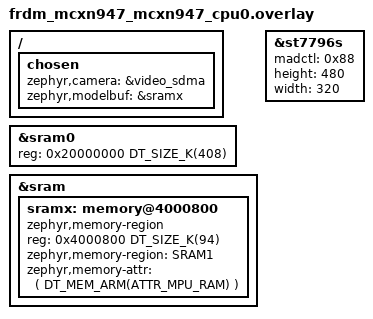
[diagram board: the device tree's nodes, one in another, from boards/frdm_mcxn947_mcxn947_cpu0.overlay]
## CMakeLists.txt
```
# Copyright 2024, NXP
#
# SPDX-License-Identifier: Apache-2.0

cmake_minimum_required(VERSION 3.20.0)

# Add shields for displays and cameras
if("${BOARD}" MATCHES "mimxrt1060_evk")
	set(SHIELD dvp_fpc24_mt9m114;rk043fn66hs_ctg)
elseif("${BOARD}" MATCHES "frdm_mcxn947")
	set(SHIELD lcd_par_s035_8080)
endif()

find_package(Zephyr REQUIRED HINTS $ENV{ZEPHYR_BASE})
project(facialdetect)

list(APPEND app_sources src/main.c)

list(APPEND app_sources src/face_det.cpp)
FILE(GLOB model_sources src/model/*.cpp)
list(APPEND app_sources ${model_sources})
list(APPEND app_sources img/image_draw.c)
list(APPEND app_sources img/image_conv.c)

zephyr_include_directories(${CMAKE_CURRENT_SOURCE_DIR}/src/model)
set(TFLITE_DIR "${CMAKE_CURRENT_SOURCE_DIR}/../../../modules/lib/tflite-micro")
zephyr_include_directories(${TFLITE_DIR})
zephyr_include_directories(${TFLITE_DIR}/third_party/flatbuffers/include)
zephyr_include_directories(${TFLITE_DIR}/third_party/gemmlowp)
zephyr_include_directories(${TFLITE_DIR}/third_party/ruy)

add_library(libtflm STATIC IMPORTED GLOBAL)
if (DEFINED CONFIG_CPU_CORTEX_M7)
	set_target_properties(libtflm PROPERTIES IMPORTED_LOCATION ${TFLITE_DIR}/lib/cm7/armgcc/libtflm.a)
elseif (DEFINED CONFIG_CPU_CORTEX_M33)
	set_target_properties(libtflm PROPERTIES IMPORTED_LOCATION ${TFLITE_DIR}/lib/cm33/armgcc/libtflm.a)
else()
	message(FATAL_ERROR "libtflm.a for this core not supported")
endif()

if (DEFINED CONFIG_MCUX_HAS_NPU)
	zephyr_include_directories(${CMAKE_CURRENT_SOURCE_DIR}/src/model/model_npu)
	zephyr_include_directories(${TFLITE_DIR}/tensorflow/lite/micro/kernels/neutron)
	zephyr_include_directories(${TFLITE_DIR}/third_party/neutron/common/include)
	zephyr_include_directories(${TFLITE_DIR}/third_party/neutron/driver/include)

	FILE(GLOB modelnpu_sources src/model/model_npu/*.cpp)
	list(APPEND app_sources ${modelnpu_sources})
	list(APPEND app_sources src/model/model_npu/model_data.s)
	list(APPEND app_sources ${TFLITE_DIR}/tensorflow/lite/micro/kernels/neutron/neutron.cpp)

	add_library(libNeutronDriver STATIC IMPORTED GLOBAL)
	set_target_properties(libNeutronDriver PROPERTIES IMPORTED_LOCATION ${TFLITE_DIR}/third_party/neutron/mcxn/libNeutronDriver.a)
	add_library(libNeutronFirmware STATIC IMPORTED GLOBAL)
	set_target_properties(libNeutronFirmware PROPERTIES IMPORTED_LOCATION ${TFLITE_DIR}/third_party/neutron/mcxn/libNeutronFirmware.a)
	target_link_libraries(app PUBLIC libNeutronDriver libNeutronFirmware)
else() # CONFIG_MCUX_HAS_NPU not defined
	zephyr_include_directories(${CMAKE_CURRENT_SOURCE_DIR}/src/model/model_sw)

	FILE(GLOB modelsw_sources src/model/model_sw/*.cpp)
	list(APPEND app_sources ${modelsw_sources})
	list(APPEND app_sources img/image_resize_nearest.c)
endif() # CONFIG_MCUX_HAS_NPU
target_link_libraries(app PUBLIC libtflm)

zephyr_include_directories(${CMAKE_CURRENT_SOURCE_DIR}/img)
zephyr_include_directories(${CMAKE_CURRENT_SOURCE_DIR}/src/font)
list(APPEND app_sources src/display.c)
list(APPEND app_sources src/convert.c)

target_compile_definitions(app PRIVATE TF_LITE_STATIC_MEMORY)
target_compile_options(app PRIVATE -Wno-psabi)
target_sources(app PRIVATE ${app_sources})
```

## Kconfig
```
# Copyright 2024 NXP
# SPDX-License-Identifier: Apache-2.0

# Config options for app

config APP_LOG_LEVEL
	int "Log Level for application"

config APP_TENSOR_ARENA_SIZE_KB
	int "size of arena in KB"
	default 200

config APP_CONVERT_DISPLAY
	bool "converts video buffer before writing to display"
	depends on DISPLAY

config APP_RESIZE_FOR_MODEL
	bool "Resizes frame before model processes"

config APP_DISPLAY_BANNER
	bool "Displays text banner on bottom of display, with inference results"
	depends on DISPLAY

config MCUX_HAS_NPU
	bool "SOC has NPU"

if APP_CONVERT_DISPLAY
	config CONVDISP_BUF_POOL_SZ_MAX
		int "Maximum size in bytes of each buffer in the CONVDISP pool"

	config CONVDISP_BUF_POOL_NUM_MAX
		int "Maximum number of buffers in the CONVDISP pool"

	config APP_USE_PXP
		bool "use PXP for conversion"

	if APP_USE_PXP
		config APP_PXP_FLIP_HORIZONTAL
			bool "uses PXP to flip frame horizontally"
	endif # APP_USE_PXP
endif # APP_CONVERT_DISPLAY

if APP_RESIZE_FOR_MODEL
	config APP_EXTRACT_WIDTH
		int "width of image extracted from camera frame in pixels"

	config APP_EXTRACT_HEIGHT
		int "height of image extracted from camera frame in pixels"
endif # APP_RESIZE_FOR_MODEL

source "Kconfig.zephyr"
```

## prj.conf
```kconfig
#
# Copyright 2024, NXP
#
# SPDX-License-Identifier: Apache-2.0
#

CONFIG_APP_LOG_LEVEL=3

CONFIG_DISPLAY=y
CONFIG_DISPLAY_LOG_LEVEL_ERR=y
CONFIG_VIDEO=y

CONFIG_LOG=y
CONFIG_SHELL=y
CONFIG_DEVICE_SHELL=y
CONFIG_PRINTK=y
CONFIG_THREAD_RUNTIME_STATS=y
CONFIG_SCHED_THREAD_USAGE=y
CONFIG_STD_CPP11=y

CONFIG_BUILD_OUTPUT_HEX=y

CONFIG_HEAP_MEM_POOL_SIZE=16384
CONFIG_NO_OPTIMIZATIONS=y
CONFIG_MAIN_STACK_SIZE=16000
CONFIG_IDLE_STACK_SIZE=1024
CONFIG_ISR_STACK_SIZE=8096

CONFIG_CPP=y
CONFIG_REQUIRES_FULL_LIBCPP=y
CONFIG_FPU=y
CONFIG_FP_HARDABI=y

# using Picolib has errors compiling C++ math
CONFIG_NEWLIB_LIBC=y
```

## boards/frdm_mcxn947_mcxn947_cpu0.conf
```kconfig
#
# Copyright 2024, NXP
#
# SPDX-License-Identifier: Apache-2.0
#

CONFIG_MCUX_HAS_NPU=y

# Workaround for issue where SDMA driver needs to start before camera, so that
# clock output will be generated for camera device
CONFIG_CHECK_INIT_PRIORITIES=n

CONFIG_HEAP_MEM_POOL_SIZE=41000

# Buffer size 320W x 15H x 2BPP x 2(SmartDMA) + 36
CONFIG_VIDEO_BUFFER_POOL_SZ_MAX=19236
CONFIG_VIDEO_BUFFER_POOL_NUM_MAX=3
```

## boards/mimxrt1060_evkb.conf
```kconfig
#
# Copyright 2024, NXP
#
# SPDX-License-Identifier: Apache-2.0
#

CONFIG_VIDEO_MCUX_CSI_INIT_PRIORITY=60
CONFIG_VIDEO_INIT_PRIORITY=61
CONFIG_CHECK_INIT_PRIORITIES=n

CONFIG_APP_CONVERT_DISPLAY=y
CONFIG_DMA=y
CONFIG_APP_USE_PXP=y
CONFIG_APP_PXP_FLIP_HORIZONTAL=y
CONFIG_APP_RESIZE_FOR_MODEL=y
CONFIG_APP_DISPLAY_BANNER=y

# Extraction is twice the model input size of 160 x 128
CONFIG_APP_EXTRACT_WIDTH=320
CONFIG_APP_EXTRACT_HEIGHT=256

# buffer size 261,120 = 480 * 272 * 2
CONFIG_CONVDISP_BUF_POOL_SZ_MAX=261120
CONFIG_CONVDISP_BUF_POOL_NUM_MAX=2
```

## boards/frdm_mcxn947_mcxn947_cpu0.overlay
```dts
/*
 * Copyright 2024, NXP
 *
 * SPDX-License-Identifier: Apache-2.0
 */

/* Resize SRAMX to avoid memory used by SmartDMA firmware */
/delete-node/ &sramx;

/ {
	chosen {
		zephyr,camera = &video_sdma;

		/* Use buffer for model to stitch camera slices together.
		 * Place model buffer in SRAMX */
		zephyr,modelbuf = &sramx;
	};
};

&sram0 {
	/* Increase size of SRAM region */
	reg = < 0x20000000 DT_SIZE_K(408) >;
};

&sram {
	sramx: memory@4000800 {
		compatible = "zephyr,memory-region", "mmio-sram";
		/* Avoid SRAMX memory used by SmartDMA firmware */
		reg = < 0x4000800  DT_SIZE_K(94) >;
		zephyr,memory-region = "SRAM1";
		zephyr,memory-attr = <( DT_MEM_ARM(ATTR_MPU_RAM) )>;
	};
};

/* Rotate the display to portrait mode */
&st7796s {
	madctl = <0x88>;
	height = <480>;
	width = <320>;
};
```

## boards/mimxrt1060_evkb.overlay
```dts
/*
 * Copyright 2024, NXP
 *
 * SPDX-License-Identifier: Apache-2.0
 */

 / {
	chosen {
		zephyr,arena = &ocram2; /* Place tensorArena in OCRAM2 */
	};
};

/* Increase DTCM for model. */
&itcm {
	reg = < 0x0 DT_SIZE_K(64) >;
};
&dtcm {
	reg = < 0x20000000 DT_SIZE_K(384) >;
};
&ocram {
	reg = < 0x20280000 DT_SIZE_K(64) >;
};
&flexram {
	flexram,bank-spec = <FLEXRAM_OCRAM>,
			    <FLEXRAM_OCRAM>,
			    <FLEXRAM_DTCM>,
			    <FLEXRAM_DTCM>,
			    <FLEXRAM_DTCM>,
			    <FLEXRAM_DTCM>,
			    <FLEXRAM_DTCM>,
			    <FLEXRAM_DTCM>,
			    <FLEXRAM_ITCM>,
			    <FLEXRAM_ITCM>,
			    <FLEXRAM_DTCM>,
			    <FLEXRAM_DTCM>,
			    <FLEXRAM_DTCM>,
			    <FLEXRAM_DTCM>,
			    <FLEXRAM_DTCM>,
			    <FLEXRAM_DTCM>;
};
```

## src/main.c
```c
/*
 * Copyright 2024, NXP
 * Copyright (c) 2019 Linaro Limited, for sample:
 *    https://github.com/zephyrproject-rtos/zephyr/blob/main/samples/subsys/video/capture/src/main.c
 *
 * Copyright (c) 2019 Jan Van Winkel <jan.van_winkel@dxplore.eu>, for sample:
 *    https://github.com/zephyrproject-rtos/zephyr/blob/main/samples/drivers/display/src/main.c
 *
 * Based on ST7789V sample:
 *    Copyright (c) 2019 Marc Reilly
 *
 * SPDX-License-Identifier: Apache-2.0
 *
 * Application Overview:
 * The main thread runs in a loop, dequeuing buffers from the video driver,
 * formatting and writing to the display, then resizing and sending to the
 * inference model for object detection.  If detected, the model returns
 * coordinates of the object, and rectangles are drawn for the display.
 * Inferencing is done in a separate thread, giving priority to updating the
 * display.
 * 
 * on MCX N947:
 * This SOC provides some challenge due to the limited RAM available.  The
 * LCD-PAR-S035 display is oriented in portrait mode to align with the camera.
 * To conserve RAM, the camera frame is shown on the upper half of the display,
 * at 320 x 240.  The lower half displays text, and is only updated with new
 * inference results.
 * 
 * To conserve RAM, the video driver buffers are partial slices of the full frame.
 * This reduces the buffer size required.  The video driver reports the number
 * of slices in a frame in caps.vbuf_per_frame.  And each buffer dequeued
 * provides frame_idx for that slice.  The LCD-PAR-S035 module is a smart
 * display, and partial frames can be written directly to the display.  Then
 * the slice buffer is copied to the input buffer for the model and converted to
 * RGB888.  That input is also resized for the model.  The rectangles are also
 * drawn on the slices, using the same video slice buffers before they are
 * written to the display.  To provide a cleaner look, the rectangle locations
 * are only changed at the start of a new frame.  And the previous rectangles
 * are "erased" completely before drawing new rectangles.
 * 
 * on RT1060:
 * This platform is easier with a large SDRAM, and plenty of room for buffers.
 * The video driver provides full frame buffers.  These are converted using the
 * PXP to flip the image horizontally, like looking in a mirror.  On this display,
 * the text is displayed in a banner at the bottom of the display, and the results
 * are updated from the inference.  The bottom of the full video buffer is
 * excluded when writing to the display, since the banner is drawn there.  After
 * writing to the display, the same buffer is passed to the inference thread. A
 * queue is used when passing this buffer.  The inference thread will get the
 * most recent buffer in that queue, and return any other buffers in that queue
 * to the video driver.  Rectangles are easier on this platform since the video
 * and display driver use a full frame.  If detected, the full rectangles are
 * drawn on each frame, and location updated after a new inference result.
 */

#include <zephyr/device.h>
#include <zephyr/devicetree.h>
#include <stdio.h>
#include <zephyr/kernel.h>
#include "FacialDetect.h"

#ifdef CONFIG_LOG
#define LOG_LEVEL CONFIG_LOG_DEFAULT_LEVEL
#include <zephyr/logging/log.h>
LOG_MODULE_REGISTER(app, CONFIG_APP_LOG_LEVEL);
#endif /* CONFIG_LOG */

struct display_buffer_descriptor strbuf_desc;

#include <zephyr/drivers/display.h>
#include <zephyr/drivers/video.h>
#include "display_app.h"
#include "convert.h"

const struct device *display_dev;

volatile static uint32_t __attribute((aligned(4))) vbuf_idx = 0;

#include "model.h"

K_THREAD_STACK_DEFINE(inf_thread_stack_area, THREAD_INF_STACKSIZE);
static struct k_thread inf_thread_data;

struct k_fifo inf_fifo;  /* FIFO for buffers to inference */

int main(void)
{
	printk("Zephyr Facial Detection Demo\r\n");
	printk("Model: %s\r\n", MODEL_GetModelName());

	struct video_buffer *buffers[CONFIG_VIDEO_BUFFER_POOL_NUM_MAX], *vbuf;
	struct display_buffer_descriptor buf_desc;
	void *convdisp_buf = NULL;
	rect_buf_params_t rect_params;

	display_dev = DEVICE_DT_GET(DT_CHOSEN(zephyr_display));
	if (!device_is_ready(display_dev)) {
		LOG_ERR("Device not ready, aborting test");
		return -1;
	}

	if (convdisp_init(DT_PROP(DT_CHOSEN(zephyr_display), width),
		DT_PROP(DT_CHOSEN(zephyr_display), height))) {
		LOG_ERR("convdisp_init() failed\n");
		return -1;
	}

	const struct device *const video = DEVICE_DT_GET(DT_CHOSEN(zephyr_camera));

	if (!device_is_ready(video)) {
		LOG_ERR("%s: device not ready.\n", video->name);
		return -1;
	}

	int i = 0;
	unsigned int frame = 0;

	LOG_DBG("- Device name: %s\n", video->name);

	/* Get capabilities */
	struct video_caps caps;
	if (video_get_caps(video, VIDEO_EP_OUT, &caps)) {
		LOG_ERR("Unable to retrieve video capabilities");
		return -1;
	}

	LOG_DBG("- Capabilities:\n");
	while (caps.format_caps[i].pixelformat) {
		const struct video_format_cap *fcap = &caps.format_caps[i];
		/* fourcc to string */
		LOG_DBG("  %c%c%c%c width [%u; %u; %u] height [%u; %u; %u]\n",
		       (char)fcap->pixelformat,
		       (char)(fcap->pixelformat >> 8),
		       (char)(fcap->pixelformat >> 16),
		       (char)(fcap->pixelformat >> 24),
		       fcap->width_min, fcap->width_max, fcap->width_step,
		       fcap->height_min, fcap->height_max, fcap->height_step);
		i++;
	}

	/* Get default/native format */
	struct video_format fmt;
	if (video_get_format(video, VIDEO_EP_OUT, &fmt)) {
		LOG_ERR("Unable to retrieve video format");
		return -1;
	}

	LOG_DBG("- Default format: %c%c%c%c %ux%u\n", (char)fmt.pixelformat,
	       (char)(fmt.pixelformat >> 8),
	       (char)(fmt.pixelformat >> 16),
	       (char)(fmt.pixelformat >> 24),
	       fmt.width, fmt.height);

	/* Size to allocate for each buffer */
	size_t bsize;
	bsize = fmt.pitch * fmt.height / caps.vbuf_per_frame;

	/* Alloc video buffers and enqueue for capture */
	for (i = 0; i < ARRAY_SIZE(buffers); i++) {
		buffers[i] = video_buffer_alloc(bsize);
		if (buffers[i] == NULL) {
			LOG_ERR("Unable to alloc video buffer");
			return -1;
		}

		video_enqueue(video, VIDEO_EP_OUT, buffers[i]);
	}

	/* configure display buffer */
	uint16_t y_step;

	y_step = fmt.height / caps.vbuf_per_frame;
	buf_desc.buf_size = bsize;
	buf_desc.width = fmt.width;
	buf_desc.pitch = fmt.width;
	buf_desc.height = y_step;
	#ifdef CONFIG_APP_DISPLAY_BANNER
		buf_desc.height -= BANNER_HEIGHT;
	#endif

	/* use a video buffer to initially draw the display brackground */
	display_background(buffers[0]->buffer);

	/* Start video capture */
	if (video_stream_start(video)) {
		LOG_ERR("Unable to start capture (interface)");
		return -1;
	}

	LOG_DBG("Capture started\n");

	/* Create inference thread */
	inf_thread_config_t inf_config;

	inf_config.frameWidth = fmt.width;
	inf_config.fullFrameHeight = fmt.height;
	inf_config.singleFrameHeight = buf_desc.height;

	k_fifo_init(&inf_fifo);

	k_thread_create(&inf_thread_data, inf_thread_stack_area,
		K_THREAD_STACK_SIZEOF(inf_thread_stack_area),
		inference_thread, &inf_config, &inf_fifo, NULL,
		THREAD_PRIORITY_INF, 0, K_FOREVER);
	k_thread_name_set(&inf_thread_data, "inference_thread");

	uint8_t inf_frame_count = 0;
	bool inference_enabled = false;

	inf_results_t infResults;
	inf_results_t *frame_infResults;
	if (caps.vbuf_per_frame > 1U) {
		/* Inference results are synced at the start of each full video
		 * frame, to keep rectangles consistent in that frame.  Display
		 * will use the local copy of the results. */
		frame_infResults = &infResults;
	} else {
		/* When video provides full frame, display can use the global
		 * inference results, and avoid copying the results every frame */
		frame_infResults = &g_InfResults;
	}

	rect_params.width = buf_desc.width;
	rect_params.height = buf_desc.height;
	rect_params.slices_per_frame = caps.vbuf_per_frame;

	while (1) {
		int err;

		/* Grab video frames */
		err = video_dequeue(video, VIDEO_EP_OUT, &vbuf, K_FOREVER);
		if (err) {
			LOG_ERR("Unable to dequeue video buf");
			return -1;
		}

		LOG_DBG("\rGot frame %u! size: %u; timestamp %u ms",
		       frame++, vbuf->bytesused, vbuf->timestamp);

		convdisp(vbuf->buffer, (uint8_t **) &convdisp_buf,
			vbuf->bytesused, K_FOREVER);

		if(caps.vbuf_per_frame > 1) {
			if(vbuf->frame_idx == 0) {
				sync_slice_rectangles(frame_infResults);
			}
		#if DT_HAS_CHOSEN(zephyr_modelbuf)
			copy_slice_to_model_input(vbuf->frame_idx,
				(uint32_t) convdisp_buf, fmt.width, y_step,
				caps.vbuf_per_frame);
		#endif /* #if DT_HAS_CHOSEN(zephyr_modelbuf) */
		}

		rect_params.buf = (uint16_t *) convdisp_buf;
		rect_params.frame_idx = vbuf->frame_idx;
		display_rectangles(&rect_params, frame_infResults);

		/* Write the video buffer out to the display */
		display_write(display_dev, 0, y_step * vbuf->frame_idx, &buf_desc, convdisp_buf);

		if(inference_enabled) {
			/* wake inf_thread if it is waiting for buffer */
			k_fifo_alloc_put(&inf_fifo, convdisp_buf);
		} else {
			if(inf_frame_count >= caps.vbuf_per_frame) {
				/* wait for first full frame before starting
				 * inference thread */
				k_fifo_alloc_put(&inf_fifo, convdisp_buf);
				k_thread_start(&inf_thread_data);
				inference_enabled = true;
			} else {
				inf_frame_count++;
				/* free buffer for next conversion */
				convdisp_enqueue(convdisp_buf);
			}
		}

		/* vbuf already used, re-use this buffer to write results to
		 * display, before giving back to video driver. */
		display_results((uint16_t *)vbuf->buffer);

		err = video_enqueue(video, VIDEO_EP_OUT, vbuf);
		if (err) {
			LOG_ERR("Unable to requeue video buf");
			return -1;
		}
	}
}
```

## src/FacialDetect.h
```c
/*
 * Copyright 2024, NXP
 *
 * SPDX-License-Identifier: Apache-2.0
 */

#if defined(__cplusplus)
extern "C" {
#endif /* __cplusplus */

#include <zephyr/kernel.h>
#include "image_utils.h"

/*******************************************************************************
 * Definitions
 ******************************************************************************/

/* Inference Thread */
#define THREAD_INF_STACKSIZE	4096
#define THREAD_PRIORITY_INF	2	/* lowest priority */

/*******************************************************************************
 * Prototypes
 ******************************************************************************/
typedef struct
{
	int frameWidth;
	int fullFrameHeight;
	int singleFrameHeight;
} inf_thread_config_t;

typedef struct
{
	ODResult_t odRets[MAX_OD_BOX_CNT];
	int odRetCnt;
	uint32_t infUs;
	uint64_t retsTimeStamp;
} inf_results_t;

void inference_thread(void *config, void *fifo, void *dummy3);

extern uint32_t static_image_addr;
extern inf_results_t g_InfResults;
extern 	const struct device *display_dev;

#include "image_utils.h"
extern ODResult_t s_odRets[];

void Model_Resize(uint8_t* srcData, int srcWidth, int srcHeight);
const char * GetBriefString(inf_results_t * results);
void sync_slice_rectangles(inf_results_t *infResults);
void copy_slice_to_model_input(uint32_t idx, uint32_t cam_slice_buffer,
	uint32_t cam_slice_width, uint32_t cam_slice_height, uint32_t max_idx);

#if defined(__cplusplus)
}
#endif /* __cplusplus */
```

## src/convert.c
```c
/*
 * Copyright 2024, NXP
 *
 * SPDX-License-Identifier: Apache-2.0
 */

#include "FacialDetect.h"
#include <zephyr/kernel.h>
#include "convert.h"

#ifdef CONFIG_APP_CONVERT_DISPLAY

K_HEAP_DEFINE(convdisp_buf_pool,
	((CONFIG_CONVDISP_BUF_POOL_SZ_MAX + 8U) *
	CONFIG_CONVDISP_BUF_POOL_NUM_MAX) + 128U);

static struct k_fifo convdisp_fifo_in;  /* free buffers for conversion */

#ifdef CONFIG_APP_USE_PXP
	#include <zephyr/drivers/dma.h>
	#include <zephyr/drivers/dma/dma_mcux_pxp.h>
	#include <zephyr/device.h>
	#include <zephyr/devicetree.h>
	#include <zephyr/dt-bindings/display/panel.h>
#ifdef CONFIG_HAS_MCUX_CACHE
	#include <fsl_cache.h>
#endif
	const struct device *pxp_dev;
	static struct dma_config pxp_dma = {0};
	static struct dma_block_config pxp_block = {0};
	static struct k_sem pxp_done;

	static void conv_pxp_callback(const struct device *dma_dev,
				void *user_data, uint32_t channel, int ret)
	{
		struct k_sem *pxp_done_sem = user_data;

		k_sem_give(pxp_done_sem);
	}
#endif /* CONFIG_APP_USE_PXP */

int convdisp_init(uint16_t panelWidth, uint16_t panelHeight) {
	uint8_t i;
	void *buf;

	/* Initialize the conversion FIFOs */
	k_fifo_init(&convdisp_fifo_in);

	for(i=0; i<CONFIG_CONVDISP_BUF_POOL_NUM_MAX; i++) {
		buf = k_heap_alloc(&convdisp_buf_pool,
			CONFIG_CONVDISP_BUF_POOL_SZ_MAX, K_FOREVER);

		if (buf == NULL) {
			return -ENOMEM;
		}

		k_fifo_alloc_put(&convdisp_fifo_in, buf);
	}

#ifdef CONFIG_APP_USE_PXP
	pxp_dev = DEVICE_DT_GET(DT_NODELABEL(pxp));

	k_sem_init(&pxp_done, 0, 1);
	if (!device_is_ready(pxp_dev)) {
		return -ENODEV;
	}

	/* DMA slot sets pixel format and rotation/flip command */
	uint8_t pixel_bytes;
	switch(DT_PROP(DT_CHOSEN(zephyr_display), pixel_format)) {
		case PANEL_PIXEL_FORMAT_BGR_565:
			pxp_dma.dma_slot = DMA_MCUX_PXP_FMT(DMA_MCUX_PXP_FMT_RGB565);
			pixel_bytes = 2;
			break;

		case PANEL_PIXEL_FORMAT_RGB_888:
			pxp_dma.dma_slot = DMA_MCUX_PXP_FMT(DMA_MCUX_PXP_FMT_RGB888);
			pixel_bytes = 4;
			break;

		default:
			/* Does not support */
			return -ENOTSUP;
	}

#ifdef CONFIG_APP_PXP_FLIP_HORIZONTAL
	/* Configure PXP to flip camera image like mirror */
	pxp_dma.linked_channel |= DMA_MCUX_PXP_FLIP(DMA_MCUX_PXP_FLIP_HORIZONTAL);
#endif

	pxp_dma.channel_direction = MEMORY_TO_MEMORY;
	pxp_dma.source_data_size =
		DT_PROP(DT_CHOSEN(zephyr_display), width) * pixel_bytes;
	pxp_dma.dest_data_size = pxp_dma.source_data_size;
	/* Burst lengths are heights of source/dest buffer in pixels */
	pxp_dma.source_burst_length = DT_PROP(DT_CHOSEN(zephyr_display), height);
	pxp_dma.dest_burst_length = pxp_dma.source_burst_length;
	pxp_dma.head_block = &pxp_block;
	pxp_dma.dma_callback = conv_pxp_callback;
	pxp_dma.user_data = &pxp_done;
#endif
	return 0;
}

void convdisp_enqueue(void *buf) {
	k_fifo_alloc_put(&convdisp_fifo_in, buf);
}

int convdisp(uint8_t *pSrc, uint8_t **pDst, uint32_t size, k_timeout_t timeout) {
	if(pSrc == NULL) {
		return -EINVAL;
	}

	/* First check for available buffer in convdisp FIFO */
	*pDst = k_fifo_get(&convdisp_fifo_in, K_NO_WAIT);

	if (*pDst == NULL) {
		/* Buffer available in inf_fifo, and not used yet by inferencing */
		*pDst = k_fifo_get(&inf_fifo, timeout);
		if (*pDst == NULL) {
			return -EAGAIN;
		}
	}
#ifdef CONFIG_APP_USE_PXP
	#ifdef CONFIG_HAS_MCUX_CACHE
		DCACHE_CleanByRange((uint32_t) pSrc, size);
	#endif

	pxp_block.source_address = (uint32_t) pSrc;
	pxp_block.dest_address = (uint32_t) *pDst;
	pxp_block.block_size = size;

	int ret = 0;
	ret = dma_config(pxp_dev, 0, &pxp_dma);
	if (ret < 0) {
		return ret;
	}

	ret = dma_start(pxp_dev, 0);
	if (ret < 0) {
		return ret;
	}
	k_sem_take(&pxp_done, timeout);
#endif /* CONFIG_APP_USE_PXP */
	
	return 0;
}

#else /* CONFIG_APP_CONVERT_DISPLAY=n */

int convdisp_init(uint16_t panelWidth, uint16_t panelHeight) {
	(void) panelHeight;
	(void) panelWidth;

	return 0;
}

void convdisp_enqueue(void *buf) {
	(void) buf;
}

int convdisp(uint8_t *pSrc, uint8_t **pDst, uint32_t size, k_timeout_t timeout) {
	(void) timeout;
	(void) size;

	*pDst = pSrc;
	return 0;
}

#endif /* CONFIG_APP_CONVERT_DISPLAY */
```

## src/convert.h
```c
/*
 * Copyright 2024, NXP
 *
 * SPDX-License-Identifier: Apache-2.0
 */

#if defined(__cplusplus)
extern "C" {
#endif /* __cplusplus */

#include <zephyr/kernel.h>
extern struct k_fifo inf_fifo;  /* FIFO for buffers to inference */

/**
 * @brief Initializes display conversion
 *
 * @param panelWidth width in pixels of display.
 * @param panelHeight height in pixels of display.
 *
 * @retval 0 Is successful.
 * @retval -ENOMEM buffer allocation failed.
 */
int convdisp_init(uint16_t panelWidth, uint16_t panelHeight);

/**
 * @brief enqueues display conversion buffer
 * 
 * Call after buffer written to display, before next conversion
 *
 * @param buf Pointer to buffer.
 */
void convdisp_enqueue(void *buf);

/**
 * @brief Converts source buffer to display buffer
 *
 * @param pSrc Pointer to input source buffer.
 * @param pDst Pointer to output destination buffer.
 * @param timeout when waiting for inf_fifo.
 *
 * @retval 0 Is successful.
 * @retval -EINVAL pSrc address invalid.
 * @retval -EAGAIN k_fifo_get() timed out.
 */
int convdisp(uint8_t *pSrc, uint8_t **pDst, uint32_t size, k_timeout_t timeout);

#if defined(__cplusplus)
}
#endif /* __cplusplus */
```

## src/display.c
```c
/*
 * Copyright (c) 2019 Jan Van Winkel <jan.van_winkel@dxplore.eu>
 * Copyright 2024, NXP
 *
 * Based on ST7789V sample:
 * Copyright (c) 2019 Marc Reilly
 *
 * SPDX-License-Identifier: Apache-2.0
 */

#include <zephyr/logging/log.h>
LOG_MODULE_REGISTER(sample, LOG_LEVEL_INF);

#include <zephyr/kernel.h>
#include <zephyr/device.h>
#include <zephyr/drivers/display.h>
#include "FacialDetect.h"
#include "display_app.h"

#include "ASCII_consolas_3618.h"
uint16_t POINT_COLOR = 0x0 << 11;
uint16_t BACK_COLOR  = 0xFFFFU;
#define  BACK_COLOR8   0xFFU
#define  RECT_COLOR32  0xFFFFFFFFU;

__attribute__ ((aligned (32))) uint16_t g_char_buf[CHAR_SIZE][CHAR_SIZE/2] = {0};
enum corner {
	TOP_LEFT,
	TOP_RIGHT,
	BOTTOM_RIGHT,
	BOTTOM_LEFT
};

typedef struct{
	uint16_t x_start;
	uint16_t y_start;
	uint16_t x_end;
	uint16_t y_end;
} area_lcd_t;

typedef void (*fill_buffer)(enum corner corner, uint8_t grey, uint8_t *buf,
			    size_t buf_size);

static struct display_buffer_descriptor buf_desc;
const uint8_t *buffer_slice;
static uint64_t s_prevTimeStamp = 0;
static int s_RetCntPrev = 0xFFFFFFFF;
static uint32_t s_prevInfUs = 0;

#ifdef CONFIG_APP_DISPLAY_BANNER
	static uint16_t banner_buf[BANNER_SIZE];
#endif

/* Declare const strings to draw on display */
#ifdef CONFIG_BOARD_FRDM_MCXN947
	const uint8_t mcxn9[] = "  MCXN94x  ";
	const struct disp_string_t str_mcxn9 = {
		.str = (uint8_t *) mcxn9,
		.width = 0,
		.height = CHAR_SIZE,
		.x = 80U,
		.y = 250U,
	};

	const uint8_t aidemo[] = "Face Detect";
	const struct disp_string_t str_aidemo = {
		.str = (uint8_t *) aidemo,
		.width = 0,
		.height = CHAR_SIZE,
		.x = 80U,
		.y = 280U,
	};

	const uint8_t npu[] = "NPU:";
	const struct disp_string_t str_npu = {
		.str = (uint8_t *) npu,
		.width = 0,
		.height = CHAR_SIZE,
		.x = 32U,
		.y = 360U,
	};

	struct disp_string_t str_results = {
		.width = 11U,
		.height = CHAR_SIZE,
		.x = 96U,
		.y = 360U,
	};
#elif ((defined CONFIG_BOARD_MIMXRT1060_EVKB) || (defined CONFIG_BOARD_MIMXRT1060_EVK))
	const uint8_t rt1060[] = "RT1060 FaceDct CM7:";
	const struct disp_string_t str_rt1060 = {
		.str = (uint8_t *) rt1060,
		.width = 0,
		.height = CHAR_SIZE,
		.x = 0U,
		.y = 272U - CHAR_SIZE,
	};

	struct disp_string_t str_results = {
		.width = 11U,
		.height = CHAR_SIZE,
		.x = 304U,
		.y = 272U - CHAR_SIZE,
	};
#else
	#error display strings not support for this board
#endif /* CONFIG_BOARD_FRDM_MCXN947 */

int display_background(const void *disp_buf)
{
#ifdef CONFIG_APP_DISPLAY_BANNER
	/* Fill the buffer with background pixels */
	(void)memset(banner_buf, BACK_COLOR8, sizeof(banner_buf));

	/* Display the banner string */
	draw_string((struct disp_string_t *) &str_rt1060, banner_buf, 
			&strbuf_desc);
	display_write(display_dev, BANNER_X, BANNER_Y, &strbuf_desc, banner_buf);

#else /* CONFIG_APP_DISPLAY_BANNER=n */
	/* Before starting video driver, use video buffers to write strings to
	 * display. */
	display_blanking_off(display_dev);

	size_t buf_size;
	struct display_capabilities capabilities;

	display_get_capabilities(display_dev, &capabilities);

	buf_size = capabilities.x_resolution;

	switch (capabilities.current_pixel_format) {
	case PIXEL_FORMAT_ARGB_8888:
		buf_size *= 4;
		break;
	case PIXEL_FORMAT_RGB_888:
		buf_size *= 3;
		break;
	case PIXEL_FORMAT_RGB_565:
		buf_size *= 2;
		break;
	case PIXEL_FORMAT_BGR_565:
		buf_size *= 2;
		break;
	case PIXEL_FORMAT_MONO01:
	case PIXEL_FORMAT_MONO10:
		buf_size /= 8;
		break;
	default:
		LOG_ERR("Unsupported pixel format. Aborting sample.");
		return 0;
	}

	/* Fill the buffer with background pixels */
	(void)memset((void *) disp_buf, BACK_COLOR8, buf_size);

	buf_desc.buf_size = buf_size;
	buf_desc.pitch = capabilities.x_resolution;
	buf_desc.width = capabilities.x_resolution;
	buf_desc.height = 1;

	/* Write the buffer to the entire display */
	for (int idx = 0; idx < capabilities.y_resolution; idx++) {
		display_write(display_dev, 0, idx, &buf_desc, disp_buf);
	}
	display_blanking_off(display_dev);

	draw_string((struct disp_string_t *) &str_mcxn9,
			(uint16_t *) disp_buf, &strbuf_desc);
	display_write(display_dev, str_mcxn9.x, str_mcxn9.y, &strbuf_desc,
			disp_buf);

	draw_string((struct disp_string_t *) &str_aidemo,
			(uint16_t *) disp_buf, &strbuf_desc);
	display_write(display_dev, str_aidemo.x, str_aidemo.y, &strbuf_desc,
			disp_buf);

	draw_string((struct disp_string_t *) &str_npu,
			(uint16_t *) disp_buf, &strbuf_desc);
	display_write(display_dev, str_npu.x, str_npu.y, &strbuf_desc,
			disp_buf);

	display_blanking_off(display_dev);
#endif /* CONFIG_APP_DISPLAY_BANNER */

	return 1;
}

void display_font_conversion(uint16_t *buf, uint16_t width, uint8_t num,
				uint8_t size, uint8_t mode) {
	uint16_t *pDst;
	uint8_t temp,t1,t,buf_x, buf_y;
	uint8_t csize=(size/8+((size%8)?1:0));

	num -= 32;
	buf_x = 0;
	buf_y = 0;

	for (uint32_t i=0;i<size/2;i++) {
		for (t = 0; t < csize; t++) {
			temp = asc2_2412[num][csize*i + t];
			for (t1 = 0; t1 < 8; t1++) {
				pDst = buf + buf_y * width + buf_x;
				if (temp & 0x80U) {
					*pDst = POINT_COLOR;
				} else if (mode == 0) {
					*pDst = BACK_COLOR;
				}

				temp <<= 1;
				buf_y++;
			}
		}

		buf_y = 0;
		buf_x++;
	}
}

void draw_string(struct disp_string_t * dstr, uint16_t *str_buf,
	struct display_buffer_descriptor * desc)
{
	uint16_t x = 0, y = 0;
	uint16_t *pDst;
	uint8_t *p = dstr->str;
	uint16_t width;
	uint8_t size = CHAR_SIZE;

	if(dstr->width) {
		width = dstr->width * CHAR_SIZE/2;
	} else {
		/* use size of string to calculate width */
		width = strlen(dstr->str) * CHAR_SIZE/2;
	}

	while((*p<='~')&&(*p>=' '))
	{
		if (x >= width) {
			x = 0;
			y += size;
		}
		if (y > dstr->height)
			break;

		pDst = str_buf + y * width + x;
		display_font_conversion(pDst, width, *p, size, 0);

		x += size/2;
		p++;
	}

	/* Config buffer descriptor */
	desc->width = width;
	desc->pitch = width;
	desc->height = dstr->height;
	desc->buf_size = desc->pitch * desc->height;
}

void draw_line(uint16_t x_start, uint16_t y_start, uint8_t size,  uint8_t dir) {
   
	uint8_t *data[size * 5 * 2];
	uint32_t data_len = 0;
	
	(void)memset(data, BACK_COLOR8, size * 5 * 2);

	if (dir == 0) {
		data_len = size * 5 * 2;
		buf_desc.buf_size = data_len;
		buf_desc.pitch = size;
		buf_desc.width = size;
		buf_desc.height = 5;

		display_write(display_dev, x_start, y_start, &buf_desc, data);
	} else if (dir == 1) {
		data_len = size * 5 * 2;
		buf_desc.buf_size = data_len;
		buf_desc.pitch = 5;
		buf_desc.width = 5;
		buf_desc.height = size;

		display_write(display_dev, x_start, y_start, &buf_desc, data);
	}

	display_blanking_off(display_dev);
}

void draw_rectangle(uint8_t x_start, uint8_t y_start, uint8_t height, uint8_t width ){

	draw_line(x_start , y_start, width,  0);
	draw_line(x_start , y_start, height ,  1);
	
	draw_line(x_start, y_start + height , width,  0);
	draw_line(x_start + width , y_start, height,  1);
}

void display_results(uint16_t *buf) {
	if(g_InfResults.retsTimeStamp != s_prevTimeStamp) {
		s_prevTimeStamp = g_InfResults.retsTimeStamp;

		/* Print inference results on display if updated*/
		if ((g_InfResults.odRetCnt != s_RetCntPrev) ||
				(g_InfResults.infUs != s_prevInfUs)) {
			str_results.str = (uint8_t *) GetBriefString(&g_InfResults);
			if (str_results.str) {
			#ifdef CONFIG_APP_DISPLAY_BANNER

				draw_string((struct disp_string_t *) &str_results,
					banner_buf, &strbuf_desc);
				display_write(display_dev, str_results.x,
					str_results.y, &strbuf_desc, banner_buf);
			#else /* CONFIG_APP_DISPLAY_BANNER=n */
				draw_string((struct disp_string_t *) &str_results,
					(uint16_t *) buf, &strbuf_desc);
				display_write(display_dev, str_results.x,
					str_results.y, &strbuf_desc, buf);

				display_blanking_off(display_dev);
			#endif /* CONFIG_APP_DISPLAY_BANNER */
			}
		}
	}
}

void draw_rect_on_slice_buffer(uint16_t* pCam, int srcW, int curY, 
	ODResult_t *pODRet, int retCnt, int slice_height) {

	int i = 0;
	int bri;

	for (i = 0; i < retCnt; i++, pODRet++) {
		bri = (int)((pODRet->score - 0.62f) * 100.0f);
		if (bri < 0)
			bri = 0;
		if (bri > 31)
			bri = 31;

		uint32_t color16 = bri | (bri*2<<5) | bri<<11;
		uint32_t color = color16 | color16<<16;
		color = RECT_COLOR32;
		uint16_t *pHorLine = 0;
		int stripeY1 = pODRet->y1 - curY;

		if (stripeY1 >= 0 && stripeY1 < slice_height) {
			for (int j = 0; j<4 && stripeY1 + j < slice_height; j++) {
				pHorLine = pCam + srcW * (j + stripeY1) + pODRet->x1;
				memset(pHorLine, color, (pODRet->x2 - pODRet->x1) * 2);
			}
		}

		int stripeY2 = pODRet->y2 - curY;
		if (stripeY2 >=0 && stripeY2 < slice_height) {
			for (int j = 0; j<4 && stripeY2 + j < slice_height; j++) {
				pHorLine = pCam + srcW * (j + stripeY2) + pODRet->x1;
				memset(pHorLine, color, (pODRet->x2 - pODRet->x1) * 2);
			}
		}

		uint16_t *pVtcLineL = pCam + pODRet->x1;
		uint16_t *pVtcLineR = pCam + pODRet->x2;

		for (int y=curY; y < curY + slice_height; y++) {
			if (y > pODRet->y1 && y < pODRet->y2) {
				memset(pVtcLineL, color, 8);
				memset(pVtcLineR, color, 8);
			}
			pVtcLineL += srcW;
			pVtcLineR += srcW;
		}
	}
}

void display_rectangles(rect_buf_params_t *rect, inf_results_t *infResults) {
	if (rect->slices_per_frame > 1U) {
		/* drawing on a slice, not the full frame */
		draw_rect_on_slice_buffer(rect->buf, rect->width,
			rect->frame_idx * rect->height, (ODResult_t *) infResults->odRets,
			infResults->odRetCnt, rect->height);
	} else {
		/* draw on the full frame */
		for (int i = 0; i < infResults->odRetCnt; i++) {
			ODResult_t* r = &infResults->odRets[i];
			IMAGE_DrawRect(rect->buf, r->x1, r->y1, (r->x2 - r->x1),
				(r->y2 - r->y1), 255, 255, 255, rect->width);
		}
	}
}
```

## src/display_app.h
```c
/*
 * Copyright 2024, NXP
 *
 * SPDX-License-Identifier: Apache-2.0
 */

#include <zephyr/kernel.h>
#include <zephyr/drivers/display.h>
#include <zephyr/device.h>
#include <zephyr/devicetree.h>

#define CHAR_SIZE 32 /* Font size for characters drawn on display */

#ifdef CONFIG_APP_DISPLAY_BANNER
	#define BANNER_WIDTH DT_PROP(DT_CHOSEN(zephyr_display), width)
	#define BANNER_HEIGHT CHAR_SIZE
	#define BANNER_SIZE BANNER_WIDTH * BANNER_HEIGHT
	#define BANNER_X 0U
	#define BANNER_Y DT_PROP(DT_CHOSEN(zephyr_display), height) - CHAR_SIZE
#endif

typedef struct
{
	uint16_t * buf;
	uint8_t frame_idx;
	uint8_t slices_per_frame;
	int width;
	int height;
} rect_buf_params_t;

/* Struct for text strings drawn on display */
struct disp_string_t {
	uint8_t * str;
	uint16_t width;		/* Width of string in characters. 0 means use sizeof() */
	uint16_t height;	/* Height of buffer */
	uint16_t x;		/* x coordinate in buffer to draw string */
	uint16_t y;		/* y coordinate in buffer to draw string */
};

int display_background(const void *disp_buf);
void draw_string(struct disp_string_t * dstr, uint16_t *str_buf,
	struct display_buffer_descriptor * desc);
void display_results(uint16_t *buf);
void display_rectangles(rect_buf_params_t *rect, inf_results_t *infResults);

extern struct display_buffer_descriptor strbuf_desc;
```

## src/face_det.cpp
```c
/*
 * Copyright 2024, NXP
 *
 * SPDX-License-Identifier: Apache-2.0
 */

#include "model.h"
#include "FacialDetect.h"
#include "output_postproc.h"
#include "yolo_post_processing.h"
#include "image_utils.h"
#include "convert.h"
#include <zephyr/linker/devicetree_regions.h>
#include <zephyr/kernel.h>
#include <stdio.h>

#ifdef CONFIG_LOG
	#include <zephyr/logging/log.h>
	LOG_MODULE_DECLARE(app);
#endif /* CONFIG_LOG */

extern "C" {

#define WND_X0 0
#define WND_Y0 0

inf_results_t g_InfResults;
static uint8_t* s_inputData;
static tensor_dims_t s_inputDims;
static 	tensor_type_t s_inputType;
static std::vector<yolo::object_detection::DetectionResult> s_results;
static yolo::DetectorPostProcess *sp_postProcess;
static 	TfLiteTensor* outputTensor[3];

#ifdef CONFIG_APP_RESIZE_FOR_MODEL
	static uint8_t extract_buf[CONFIG_APP_EXTRACT_WIDTH *
		CONFIG_APP_EXTRACT_HEIGHT * 3U]; /* in RGB888 format */

void Model_Resize(uint8_t* srcData, int srcWidth, int srcHeight) {
	uint32_t x0, y0;

	/* center extraction in camera frame */
	x0 = (srcWidth - CONFIG_APP_EXTRACT_WIDTH) / 2;
	y0 = (srcHeight - CONFIG_APP_EXTRACT_HEIGHT) / 2;

	IMAGE_ExtractRect(extract_buf, x0, y0, CONFIG_APP_EXTRACT_WIDTH,
		CONFIG_APP_EXTRACT_HEIGHT, (const uint16_t*) srcData, srcWidth);

	IMAGE_Resize(extract_buf, CONFIG_APP_EXTRACT_WIDTH,
		CONFIG_APP_EXTRACT_HEIGHT, s_inputData,
		s_inputDims.data[2], s_inputDims.data[1], s_inputDims.data[3]);
}
#else /* CONFIG_APP_RESIZE_FOR_MODEL=n*/
void Model_Resize(uint8_t* srcData, int srcWidth, int srcHeight) {
	(void) srcData;
	(void) srcWidth;
	(void) srcHeight;
}
#endif /* CONFIG_APP_RESIZE_FOR_MODEL */

void Rgb565StridedToRgb888(const uint16_t* pIn, int srcW, int wndW, int wndH, int wndX0, int wndY0,
	uint8_t* p888, int stride, uint8_t isSub128) {
	const uint16_t* pSrc = pIn;
	uint32_t datIn, datOut, datOuts[3];
	uint8_t* p888out = p888;

	for (int y = wndY0,y1=(wndH-wndY0)/stride-wndY0; y < wndH; y += stride,y1--) {
		pSrc = pIn + srcW * y + wndX0;

		for (int x = 0; x < wndW; x += stride * 4) {
			datIn = pSrc[0];
			pSrc += stride;
			datOuts[0] = (datIn & 31) << 19| (datIn & 63 << 5) << 5 | ((datIn>>8) & 0xf8);

			datIn = pSrc[0];
			pSrc += stride;
			datOut = (datIn & 31) << 19| (datIn & 63 << 5) << 5 | ((datIn>>8) & 0xf8);
			datOuts[0] |= datOut << 24;
			datOuts[1] = datOut >> 8;

			datIn = pSrc[0];
			pSrc += stride;
			datOut = (datIn & 31) << 19| (datIn & 63 << 5) << 5 | ((datIn>>8) & 0xf8);
			datOuts[1] |= (datOut << 16) & 0xFFFF0000;
			datOuts[2] = datOut >> 16;

			datIn = pSrc[0];
			pSrc += stride;
			datOut = (datIn & 31) << 19| (datIn & 63 << 5) << 5 | ((datIn>>8) & 0xf8);

			datOuts[2] |= datOut << 8;

			if (isSub128) {
				// subtract 128 bytewisely, equal to XOR with 0x80
				datOuts[0] ^= 0x80808080;
				datOuts[1] ^= 0x80808080;
				datOuts[2] ^= 0x80808080;
			}
			memcpy(p888out, datOuts, 3 * 4);
			p888out += 3 * 4;
		}
	}
}

#if DT_HAS_CHOSEN(zephyr_modelbuf)
/* Place the buffer for the model in a specific linker memory region */
static uint8_t model_input_buf[MODEL_IN_W*MODEL_IN_H*MODEL_IN_C]
	Z_GENERIC_SECTION(LINKER_DT_NODE_REGION_NAME(DT_CHOSEN(zephyr_modelbuf)))
	= {0};


void copy_slice_to_model_input(uint32_t idx, uint32_t cam_slice_buffer,
	uint32_t cam_slice_width, uint32_t cam_slice_height, uint32_t max_idx)
{
	static uint8_t* pCurDat;
	uint32_t curY;
	uint32_t s_imgStride = cam_slice_width / MODEL_IN_W;
	uint32_t ndx = idx;
	curY = ndx * cam_slice_height;
	int wndY = (s_imgStride - (curY - WND_Y0) % s_imgStride) % s_imgStride;

	if (idx > max_idx)
		return;

	pCurDat = model_input_buf + 3 * ((cam_slice_height * ndx + wndY) *
		cam_slice_width / s_imgStride / s_imgStride);

	if (curY + cam_slice_height >= WND_Y0){
		if (MODEL_IN_COLOR_BGR == 1) {
			//Rgb565StridedToBgr888((uint16_t*)cam_slice_buffer, cam_slice_width, cam_slice_width, cam_slice_height, WND_X0, wndY, pCurDat, s_imgStride, 1);
		}else {
			Rgb565StridedToRgb888((uint16_t*)cam_slice_buffer,
				cam_slice_width, cam_slice_width,
				cam_slice_height, WND_X0, wndY, pCurDat,
				s_imgStride, 1);
		}
	}
}
#endif /* DT_HAS_CHOSEN(zephyr_modelbuf) */

void MODEL_ODLogResult(const ODResult_t *p, int retCnt)
{
	LOG_INF("Found boxes count %d\r\n",retCnt);
	for (int i=0; i<retCnt; i++,p++) {
		LOG_INF("%0.2f%%, x1: %d, y1: %d, x2: %d, y2: %d\r\n",
		(double)(p->score*100.0f), p->x1, p->y1, p->x2, p->y2);
	}
}

const char * GetBriefString(inf_results_t * results) {
	static char sz[26];
	sprintf(sz, "%dobj,%04dms", results->odRetCnt,
		((int)results->infUs)/1000);
	sz[11] = 0;
	return sz;
}

void init_face_det(int originalWidth, int originalHeight)
{
	size_t arenaSize;

	if (MODEL_Init() != kStatus_Success)
	{
		LOG_ERR("Failed initializing model");
		for (;;) {}
	}

	size_t usedSize = MODEL_GetArenaUsedBytes(&arenaSize);
	LOG_INF("\r\n%d/%d kB (%0.2f%%) tensor arena used\r\n", usedSize / 1024,
		arenaSize / 1024, 100.0*usedSize/arenaSize);

	s_inputData = MODEL_GetInputTensorData(&s_inputDims, &s_inputType);
	uint32_t out_size = MODEL_GetOutputSize();

	static yolo::object_detection::PostProcessParams postProcessParams =
		yolo::object_detection::PostProcessParams {
		.inputImgRows = (int) s_inputDims.data[1],
		.inputImgCols =	(int) s_inputDims.data[2],
		.output_size = (int) out_size,
		.originalImageWidth = originalWidth,
		.originalImageHeight = originalHeight,
		.threshold = 0.70,
		.nms = 0.45,
		.numClasses = 1,
	#if SERVO_ENABLE
		.topN = 1
	#else
		.topN = 0
	#endif
	};

	float *anchors = MODEL_GetAnchors();
	for (uint32_t i=0; i < out_size; i ++)
	{
		outputTensor[i] = MODEL_GetOutputTensor(i);
		postProcessParams.anchors[i][0] = *(anchors + 6*i);
		postProcessParams.anchors[i][1] = *(anchors + 6*i + 1);
		postProcessParams.anchors[i][2] = *(anchors + 6*i + 2);
		postProcessParams.anchors[i][3] = *(anchors + 6*i + 3);
		postProcessParams.anchors[i][4] = *(anchors + 6*i + 4);
		postProcessParams.anchors[i][5] = *(anchors + 6*i + 5);
	}

	static yolo::DetectorPostProcess postProcess = 
		yolo::DetectorPostProcess((const TfLiteTensor**)outputTensor,
		s_results, postProcessParams);
	sp_postProcess = &postProcess;
}

void face_det(uint8_t *pSrc, int srcWidth, int srcHeight)
{
	inf_results_t InfResults;
	k_thread_runtime_stats_t stats_inf_thread;

#if DT_HAS_CHOSEN(zephyr_modelbuf)
	uint8_t *buf = 0;

	/* Copy intermediate buffer of camera slices to buffer used by model */
	memset(s_inputData,0,s_inputDims.data[1]*s_inputDims.data[2]*s_inputDims.data[3]);
	buf = s_inputData + (s_inputDims.data[1] - MODEL_IN_H) /2 * MODEL_IN_W * MODEL_IN_C;
	memcpy(buf, model_input_buf, MODEL_IN_W*MODEL_IN_H*MODEL_IN_C);
#endif /* DT_HAS_CHOSEN(zephyr_modelbuf) */

#ifdef CONFIG_APP_RESIZE_FOR_MODEL
	Model_Resize((uint8_t *)pSrc, srcWidth, srcHeight);
	MODEL_ConvertInput(s_inputData, &s_inputDims, s_inputType);
#endif

	s_results.clear();
	k_thread_runtime_stats_get(k_current_get(), &stats_inf_thread);
	uint64_t startTime = stats_inf_thread.execution_cycles;
	MODEL_RunInference();
	k_thread_runtime_stats_get(k_current_get(), &stats_inf_thread);
	InfResults.retsTimeStamp = stats_inf_thread.execution_cycles;

	InfResults.infUs = k_cyc_to_us_ceil32(InfResults.retsTimeStamp - startTime);
	InfResults.odRetCnt = 0;
	if (!sp_postProcess->DoPostProcess()) {
		LOG_ERR("Post-processing failed.");
		InfResults.odRetCnt = 0;
	}

	for (const auto& result: s_results) {
		if(result.m_normalisedVal > BOX_SCORE_THRESHOLD) { //score of box
			ODResult_t * odRet;
			odRet = &InfResults.odRets[InfResults.odRetCnt];
			odRet->x1 = result.m_x0;
			odRet->x2 = result.m_x0 + result.m_w;
			odRet->y1 = result.m_y0;
			odRet->y2 = result.m_y0 + result.m_h;
			odRet->score = result.m_normalisedVal;
		#if SERVO_ENABLE
			if((result.m_w * result.m_h) > area_max){
				servo_motor_set_pos((uint16_t)(result.m_x0 + (int(result.m_w) >> 1)),(uint16_t)(result.m_y0 + (int(result.m_h) >> 1)));
				area_max = result.m_w * result.m_h;

			}
		#endif
			InfResults.odRetCnt ++;
		}
	}

	if (InfResults.odRetCnt > 0) {
	#if SERVO_ENABLE
		servo_motor_set_cnt(1);
	#endif
		MODEL_ODLogResult(InfResults.odRets, InfResults.odRetCnt);
		LOG_INF("Inference time %d\r\n", InfResults.infUs);
	}

	/* Copy inference results to global struct for other threads */
	k_sched_lock();
	memcpy(&g_InfResults, &InfResults, sizeof(InfResults));
	k_sched_unlock();
}

void inference_thread(void *config, void *fifo, void *dummy3) {

	uint8_t *inf_buf = NULL, *next_buf = NULL;
	struct k_fifo *inf_fifo = (struct k_fifo *) fifo;
	inf_thread_config_t *inf_config = (inf_thread_config_t *) config;

	init_face_det(inf_config->frameWidth, inf_config->fullFrameHeight);

	while(1) {
		inf_buf = (uint8_t *) k_fifo_get(inf_fifo, K_FOREVER);
		if(inf_buf == NULL) {
			LOG_ERR("k_fifo_get() returned NULL in inference_thread\n");
			return;
		}

		/* Inference the latest buffer in FIFO, check FIFO for more */
		do {
			next_buf = (uint8_t *) k_fifo_get(inf_fifo, K_NO_WAIT);
			if (next_buf != NULL) {
				/* free older buffer for next conversion */
				convdisp_enqueue(inf_buf);
				inf_buf = next_buf;
			}
		} while (next_buf != NULL);

		face_det(inf_buf, inf_config->frameWidth, inf_config->singleFrameHeight);
		convdisp_enqueue(inf_buf);

		/* give other threads chance to execute */
		k_sleep(K_MSEC(10));
	}
}

void sync_slice_rectangles(inf_results_t *infResults) {
	if (infResults->odRetCnt == 0) {
		/* Copy Inference results to slice rectangle copy for this
		 * full frame. */
		memcpy(infResults, &g_InfResults, sizeof(g_InfResults));
	} else {
		if (infResults->retsTimeStamp != g_InfResults.retsTimeStamp) {
			/* Results updated since last sync, but older slices on
			 * display are showing last rectangle.  Set odRetCnt to
			 * 0 to remove all rectangles on this frame.  Results
			 * will sync on the next full frame */
			infResults->odRetCnt = 0;
		}
	}
}

} /* extern "C" */
```
